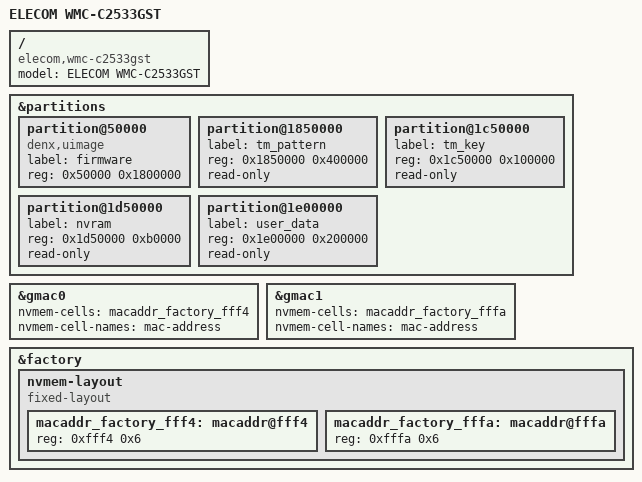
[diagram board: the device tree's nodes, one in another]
// SPDX-License-Identifier: GPL-2.0-or-later OR MIT

#include "mt7621_elecom_wrc-gs-2pci.dtsi"

/ {
	compatible = "elecom,wmc-c2533gst", "mediatek,mt7621-soc";
	model = "ELECOM WMC-C2533GST";
};

&partitions {
	partition@50000 {
		compatible = "denx,uimage";
		label = "firmware";
		reg = <0x50000 0x1800000>;
	};

	partition@1850000 {
		label = "tm_pattern";
		reg = <0x1850000 0x400000>;
		read-only;
	};

	partition@1c50000 {
		label = "tm_key";
		reg = <0x1c50000 0x100000>;
		read-only;
	};

	partition@1d50000 {
		label = "nvram";
		reg = <0x1d50000 0xb0000>;
		read-only;
	};

	partition@1e00000 {
		label = "user_data";
		reg = <0x1e00000 0x200000>;
		read-only;
	};
};

&gmac0 {
	nvmem-cells = <&macaddr_factory_fff4>;
	nvmem-cell-names = "mac-address";
};

&gmac1 {
	nvmem-cells = <&macaddr_factory_fffa>;
	nvmem-cell-names = "mac-address";
};

&factory {
	nvmem-layout {
		compatible = "fixed-layout";
		#address-cells = <1>;
		#size-cells = <1>;

		macaddr_factory_fff4: macaddr@fff4 {
			reg = <0xfff4 0x6>;
		};

		macaddr_factory_fffa: macaddr@fffa {
			reg = <0xfffa 0x6>;
		};
	};
};
